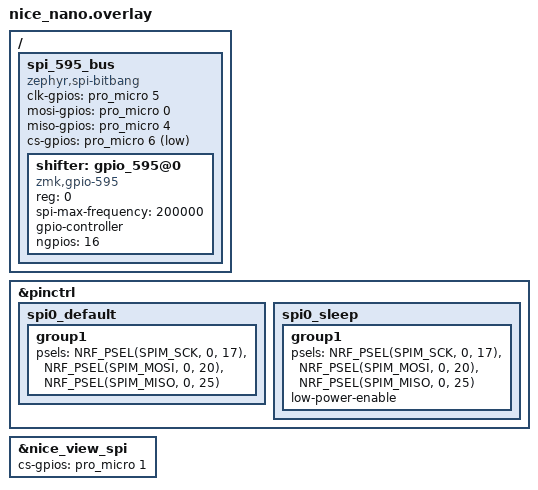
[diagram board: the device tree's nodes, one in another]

 / {
    spi_595_bus: spi_595_bus {
        compatible = "zephyr,spi-bitbang";
        status = "okay";

        /* 595 wiring:
         *   SERIAL OUTPUT (MISO) → D0
         *   SRCLK→ D5
         *   RCLK → D6 (latch)
         *   MISO → D4 (unused, but required)
         */
        clk-gpios  = <&pro_micro 5 GPIO_ACTIVE_HIGH>;  /* D5: SHCP (shift clock) */
        mosi-gpios = <&pro_micro 0 GPIO_ACTIVE_HIGH>;  /* D0: SERIAL OUT */
        miso-gpios = <&pro_micro 4 GPIO_ACTIVE_HIGH>;  /* unused, but required */

        cs-gpios   = <&pro_micro 6 GPIO_ACTIVE_LOW>;   /* D6: STCP (latch clock) */

        #address-cells = <1>;
        #size-cells = <0>;

        shifter: gpio_595@0 {
            compatible = "zmk,gpio-595";
            status = "okay";

            reg = <0>;                  /* first entry in cs-gpios */
            spi-max-frequency = <200000>;

            gpio-controller;
            #gpio-cells = <2>;
            ngpios = <16>;              /* 2×74HC595 */
        };
    };
};

/* Override nice_view_adapter SPI pin assignments:
 * Your board has D2 and D3 swapped physically.
 *
 * nice!nano defaults (reference):
 *   SCK  = P0.20 (D3)
 *   MOSI = P0.17 (D2)
 *
 * Your wiring:
 *   SCK - blue wire - physically on D2 = P0.17
 *   MOSI - brown wire - physically on D3 = P0.20
 */

&pinctrl {
    /* Replace the pinctrl groups used by spi0 */
    /delete-node/ spi0_default;
    /delete-node/ spi0_sleep;

    spi0_default: spi0_default {
        group1 {
            psels =
                <NRF_PSEL(SPIM_SCK,  0, 17)>,
                <NRF_PSEL(SPIM_MOSI, 0, 20)>,
                <NRF_PSEL(SPIM_MISO, 0, 25)>;
        };
    };

    spi0_sleep: spi0_sleep {
        group1 {
            psels =
                <NRF_PSEL(SPIM_SCK,  0, 17)>,
                <NRF_PSEL(SPIM_MOSI, 0, 20)>,
                <NRF_PSEL(SPIM_MISO, 0, 25)>;
            low-power-enable;
        };
    };
};

/* nice_view_spi is a label created by the upstream nice_view_adapter overlay.
 * We keep CS the same; change only if you wired CS elsewhere or need polarity change.
 */
&nice_view_spi {
    cs-gpios = <&pro_micro 1 GPIO_ACTIVE_HIGH>;
};

